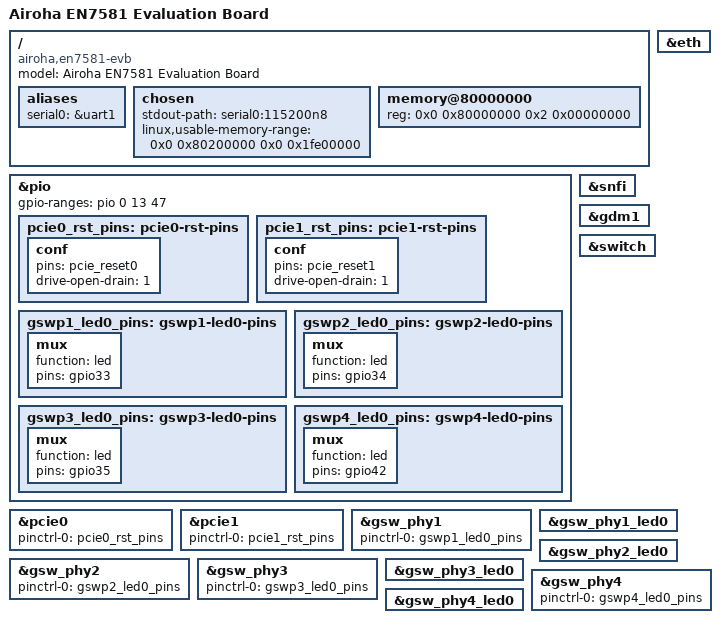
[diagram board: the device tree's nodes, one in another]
// SPDX-License-Identifier: (GPL-2.0-only OR BSD-2-Clause)
/dts-v1/;

/* Bootloader installs ATF here */
/memreserve/ 0x80000000 0x200000;

#include <dt-bindings/leds/common.h>
#include "en7581.dtsi"

/ {
	model = "Airoha EN7581 Evaluation Board";
	compatible = "airoha,en7581-evb", "airoha,en7581";

	aliases {
		serial0 = &uart1;
	};

	chosen {
		stdout-path = "serial0:115200n8";
		linux,usable-memory-range = <0x0 0x80200000 0x0 0x1fe00000>;
	};

	memory@80000000 {
		device_type = "memory";
		reg = <0x0 0x80000000 0x2 0x00000000>;
	};
};

&pio {
	gpio-ranges = <&pio 0 13 47>;

	pcie0_rst_pins: pcie0-rst-pins {
		conf {
			pins = "pcie_reset0";
			drive-open-drain = <1>;
		};
	};

	pcie1_rst_pins: pcie1-rst-pins {
		conf {
			pins = "pcie_reset1";
			drive-open-drain = <1>;
		};
	};

	gswp1_led0_pins: gswp1-led0-pins {
		mux {
			function = "led";
			pins = "gpio33";
		};
	};

	gswp2_led0_pins: gswp2-led0-pins {
		mux {
			function = "led";
			pins = "gpio34";
		};
	};

	gswp3_led0_pins: gswp3-led0-pins {
		mux {
			function = "led";
			pins = "gpio35";
		};
	};

	gswp4_led0_pins: gswp4-led0-pins {
		mux {
			function = "led";
			pins = "gpio42";
		};
	};
};

&snfi {
	status = "okay";
};

&pcie0 {
	pinctrl-names = "default";
	pinctrl-0 = <&pcie0_rst_pins>;
	status = "okay";
};

&pcie1 {
	pinctrl-names = "default";
	pinctrl-0 = <&pcie1_rst_pins>;
	status = "okay";
};

&eth {
	status = "okay";
};

&gdm1 {
	status = "okay";
};

&switch {
	status = "okay";
};

&gsw_phy1 {
	pinctrl-names = "led";
	pinctrl-0 = <&gswp1_led0_pins>;
	status = "okay";
};

&gsw_phy1_led0 {
	status = "okay";
};

&gsw_phy2 {
	pinctrl-names = "led";
	pinctrl-0 = <&gswp2_led0_pins>;
	status = "okay";
};

&gsw_phy2_led0 {
	status = "okay";
};

&gsw_phy3 {
	pinctrl-names = "led";
	pinctrl-0 = <&gswp3_led0_pins>;
	status = "okay";
};

&gsw_phy3_led0 {
	status = "okay";
};

&gsw_phy4 {
	pinctrl-names = "led";
	pinctrl-0 = <&gswp4_led0_pins>;
	status = "okay";
};

&gsw_phy4_led0 {
	status = "okay";
};
